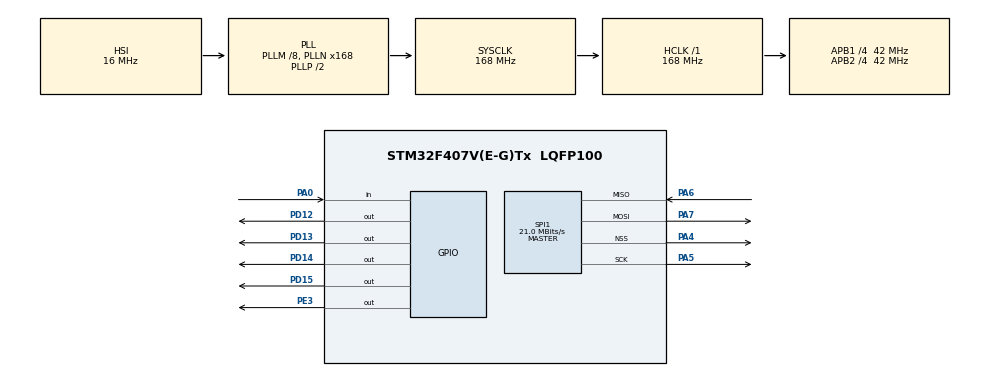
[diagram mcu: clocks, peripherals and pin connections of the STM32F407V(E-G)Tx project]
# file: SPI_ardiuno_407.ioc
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Dma.Request0=SPI1_RX
Dma.Request1=SPI1_TX
Dma.SPI1_RX.0.Direction=DMA_PERIPH_TO_MEMORY
Dma.SPI1_RX.0.FIFOMode=DMA_FIFOMODE_DISABLE
Dma.SPI1_RX.0.Instance=DMA2_Stream0
Dma.SPI1_RX.0.MemDataAlignment=DMA_MDATAALIGN_BYTE
Dma.SPI1_RX.0.MemInc=DMA_MINC_ENABLE
Dma.SPI1_RX.0.Mode=DMA_NORMAL
Dma.SPI1_RX.0.PeriphDataAlignment=DMA_PDATAALIGN_BYTE
Dma.SPI1_RX.0.PeriphInc=DMA_PINC_DISABLE
Dma.SPI1_RX.0.Priority=DMA_PRIORITY_LOW
Dma.SPI1_TX.1.Direction=DMA_MEMORY_TO_PERIPH
Dma.SPI1_TX.1.FIFOMode=DMA_FIFOMODE_DISABLE
Dma.SPI1_TX.1.Instance=DMA2_Stream3
Dma.SPI1_TX.1.MemDataAlignment=DMA_MDATAALIGN_BYTE
Dma.SPI1_TX.1.MemInc=DMA_MINC_ENABLE
Dma.SPI1_TX.1.Mode=DMA_NORMAL
Dma.SPI1_TX.1.PeriphDataAlignment=DMA_PDATAALIGN_BYTE
Dma.SPI1_TX.1.PeriphInc=DMA_PINC_DISABLE
Dma.SPI1_TX.1.Priority=DMA_PRIORITY_LOW
Mcu.Family=STM32F4
Mcu.Name=STM32F407V(E-G)Tx
Mcu.Package=LQFP100
NVIC.DMA2_Stream0_IRQn=true\:0\:0\:false\:false\:true\:false\:true
NVIC.DMA2_Stream3_IRQn=true\:0\:0\:false\:false\:true\:false\:true
NVIC.PriorityGroup=NVIC_PRIORITYGROUP_4
NVIC.SPI1_IRQn=true\:0\:0\:false\:false\:true\:true\:true
PA0-WKUP.Signal=GPIO_Input
PA4.Mode=NSS_Signal_Hard_Output
PA4.Signal=SPI1_NSS
PA5.Mode=Full_Duplex_Master
PA5.Signal=SPI1_SCK
PA6.Mode=Full_Duplex_Master
PA6.Signal=SPI1_MISO
PA7.Mode=Full_Duplex_Master
PA7.Signal=SPI1_MOSI
PC14-OSC32_IN.Mode=LSE-External-Clock-Source
PC14-OSC32_IN.Signal=RCC_OSC32_IN
PC15-OSC32_OUT.Mode=LSE-External-Clock-Source
PC15-OSC32_OUT.Signal=RCC_OSC32_OUT
PD12.Signal=GPIO_Output
PD13.Signal=GPIO_Output
PD14.Signal=GPIO_Output
PD15.Signal=GPIO_Output
PE3.Signal=GPIO_Output
ProjectManager.HeapSize=0x200
ProjectManager.StackSize=0x400
ProjectManager.TargetToolchain=STM32CubeIDE
RCC.48MHZClocksFreq_Value=84000000
RCC.AHBFreq_Value=168000000
RCC.APB1CLKDivider=RCC_HCLK_DIV4
RCC.APB1Freq_Value=42000000
RCC.APB1TimFreq_Value=84000000
RCC.APB2CLKDivider=RCC_HCLK_DIV4
RCC.APB2Freq_Value=42000000
RCC.APB2TimFreq_Value=84000000
RCC.CortexFreq_Value=168000000
RCC.HCLKFreq_Value=168000000
RCC.HSE_VALUE=25000000
RCC.HSI_VALUE=16000000
RCC.LSE_VALUE=32768
RCC.PLLM=8
RCC.PLLN=168
RCC.SYSCLKFreq_VALUE=168000000
RCC.SYSCLKSource=RCC_SYSCLKSOURCE_PLLCLK
RCC.VCOOutputFreq_Value=336000000
SPI1.BaudRatePrescaler=SPI_BAUDRATEPRESCALER_2
SPI1.CalculateBaudRate=21.0 MBits/s
SPI1.Direction=SPI_DIRECTION_2LINES
SPI1.Mode=SPI_MODE_MASTER
SPI1.VirtualNSS=VM_NSSHARD
SPI1.VirtualType=VM_MASTER
board=custom

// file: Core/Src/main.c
/* USER CODE BEGIN Header */
/**
  ******************************************************************************
  * @file           : main.c
  * @brief          : Main program body
  ******************************************************************************
  * @attention
  *
  * <h2><center>&copy; Copyright (c) 2022 STMicroelectronics.
  * All rights reserved.</center></h2>
  *
  * This software component is licensed by ST under BSD 3-Clause license,
  * the "License"; You may not use this file except in compliance with the
  * License. You may obtain a copy of the License at:
  *                        opensource.org/licenses/BSD-3-Clause
  *
  ******************************************************************************
  */
/* USER CODE END Header */
#include "main.h"

SPI_HandleTypeDef hspi1;
DMA_HandleTypeDef hdma_spi1_rx;
DMA_HandleTypeDef hdma_spi1_tx;

/* USER CODE BEGIN PV */
uint8_t Tx_buff[20],i=0;
/* USER CODE END PV */

void SystemClock_Config(void);
static void MX_GPIO_Init(void);
static void MX_DMA_Init(void);
static void MX_SPI1_Init(void);

int main(void)
{

  /* MCU Configuration--------------------------------------------------------*/

  /* Reset of all peripherals, Initializes the Flash interface and the Systick. */
  HAL_Init();

  /* Configure the system clock */
  SystemClock_Config();

  /* Initialize all configured peripherals */
  MX_GPIO_Init();
  MX_DMA_Init();
  MX_SPI1_Init();

  /* Infinite loop */
  /* USER CODE BEGIN WHILE */
  while (1)
  {
	  HAL_GPIO_WritePin(GPIOE, GPIO_PIN_3, GPIO_PIN_RESET);
	  sprintf(Tx_buff,"tx data buff: %d\r\n",i);
	  HAL_SPI_Transmit(&hspi1, Tx_buff, strlen(Tx_buff), 1000);
	  HAL_GPIO_WritePin(GPIOE, GPIO_PIN_3, GPIO_PIN_SET);

	  HAL_GPIO_TogglePin(GPIOD, GPIO_PIN_13);
	  HAL_Delay(2000);
	  i++;
    /* USER CODE END WHILE */

  }
}

void SystemClock_Config(void)
{
  RCC_OscInitTypeDef RCC_OscInitStruct = {0};
  RCC_ClkInitTypeDef RCC_ClkInitStruct = {0};

  /** Configure the main internal regulator output voltage
  */
  __HAL_RCC_PWR_CLK_ENABLE();
  __HAL_PWR_VOLTAGESCALING_CONFIG(PWR_REGULATOR_VOLTAGE_SCALE1);
  /** Initializes the RCC Oscillators according to the specified parameters
  * in the RCC_OscInitTypeDef structure.
  */
  RCC_OscInitStruct.OscillatorType = RCC_OSCILLATORTYPE_HSI;
  RCC_OscInitStruct.HSIState = RCC_HSI_ON;
  RCC_OscInitStruct.HSICalibrationValue = RCC_HSICALIBRATION_DEFAULT;
  RCC_OscInitStruct.PLL.PLLState = RCC_PLL_ON;
  RCC_OscInitStruct.PLL.PLLSource = RCC_PLLSOURCE_HSI;
  RCC_OscInitStruct.PLL.PLLM = 8;
  RCC_OscInitStruct.PLL.PLLN = 168;
  RCC_OscInitStruct.PLL.PLLP = RCC_PLLP_DIV2;
  RCC_OscInitStruct.PLL.PLLQ = 4;
  if (HAL_RCC_OscConfig(&RCC_OscInitStruct) != HAL_OK)
  {
    Error_Handler();
  }
  /** Initializes the CPU, AHB and APB buses clocks
  */
  RCC_ClkInitStruct.ClockType = RCC_CLOCKTYPE_HCLK|RCC_CLOCKTYPE_SYSCLK
                              |RCC_CLOCKTYPE_PCLK1|RCC_CLOCKTYPE_PCLK2;
  RCC_ClkInitStruct.SYSCLKSource = RCC_SYSCLKSOURCE_PLLCLK;
  RCC_ClkInitStruct.AHBCLKDivider = RCC_SYSCLK_DIV1;
  RCC_ClkInitStruct.APB1CLKDivider = RCC_HCLK_DIV4;
  RCC_ClkInitStruct.APB2CLKDivider = RCC_HCLK_DIV4;

  if (HAL_RCC_ClockConfig(&RCC_ClkInitStruct, FLASH_LATENCY_5) != HAL_OK)
  {
    Error_Handler();
  }
}

static void MX_SPI1_Init(void)
{

  /* SPI1 parameter configuration*/
  hspi1.Instance = SPI1;
  hspi1.Init.Mode = SPI_MODE_MASTER;
  hspi1.Init.Direction = SPI_DIRECTION_2LINES;
  hspi1.Init.DataSize = SPI_DATASIZE_8BIT;
  hspi1.Init.CLKPolarity = SPI_POLARITY_LOW;
  hspi1.Init.CLKPhase = SPI_PHASE_1EDGE;
  hspi1.Init.NSS = SPI_NSS_HARD_OUTPUT;
  hspi1.Init.BaudRatePrescaler = SPI_BAUDRATEPRESCALER_2;
  hspi1.Init.FirstBit = SPI_FIRSTBIT_MSB;
  hspi1.Init.TIMode = SPI_TIMODE_DISABLE;
  hspi1.Init.CRCCalculation = SPI_CRCCALCULATION_DISABLE;
  hspi1.Init.CRCPolynomial = 10;
  if (HAL_SPI_Init(&hspi1) != HAL_OK)
  {
    Error_Handler();
  }

}

static void MX_DMA_Init(void)
{

  /* DMA controller clock enable */
  __HAL_RCC_DMA2_CLK_ENABLE();

  /* DMA interrupt init */
  /* DMA2_Stream0_IRQn interrupt configuration */
  HAL_NVIC_SetPriority(DMA2_Stream0_IRQn, 0, 0);
  HAL_NVIC_EnableIRQ(DMA2_Stream0_IRQn);
  /* DMA2_Stream3_IRQn interrupt configuration */
  HAL_NVIC_SetPriority(DMA2_Stream3_IRQn, 0, 0);
  HAL_NVIC_EnableIRQ(DMA2_Stream3_IRQn);

}

static void MX_GPIO_Init(void)
{
  GPIO_InitTypeDef GPIO_InitStruct = {0};

  /* GPIO Ports Clock Enable */
  __HAL_RCC_GPIOE_CLK_ENABLE();
  __HAL_RCC_GPIOC_CLK_ENABLE();
  __HAL_RCC_GPIOA_CLK_ENABLE();
  __HAL_RCC_GPIOD_CLK_ENABLE();

  /*Configure GPIO pin Output Level */
  HAL_GPIO_WritePin(GPIOE, GPIO_PIN_3, GPIO_PIN_RESET);

  /*Configure GPIO pin Output Level */
  HAL_GPIO_WritePin(GPIOD, GPIO_PIN_12|GPIO_PIN_13|GPIO_PIN_14|GPIO_PIN_15, GPIO_PIN_RESET);

  /*Configure GPIO pin : PE3 */
  GPIO_InitStruct.Pin = GPIO_PIN_3;
  GPIO_InitStruct.Mode = GPIO_MODE_OUTPUT_PP;
  GPIO_InitStruct.Pull = GPIO_NOPULL;
  GPIO_InitStruct.Speed = GPIO_SPEED_FREQ_LOW;
  HAL_GPIO_Init(GPIOE, &GPIO_InitStruct);

  /*Configure GPIO pin : PA0 */
  GPIO_InitStruct.Pin = GPIO_PIN_0;
  GPIO_InitStruct.Mode = GPIO_MODE_INPUT;
  GPIO_InitStruct.Pull = GPIO_NOPULL;
  HAL_GPIO_Init(GPIOA, &GPIO_InitStruct);

  /*Configure GPIO pins : PD12 PD13 PD14 PD15 */
  GPIO_InitStruct.Pin = GPIO_PIN_12|GPIO_PIN_13|GPIO_PIN_14|GPIO_PIN_15;
  GPIO_InitStruct.Mode = GPIO_MODE_OUTPUT_PP;
  GPIO_InitStruct.Pull = GPIO_NOPULL;
  GPIO_InitStruct.Speed = GPIO_SPEED_FREQ_LOW;
  HAL_GPIO_Init(GPIOD, &GPIO_InitStruct);

}

void Error_Handler(void)
{
  __disable_irq();
  while (1)
  {
  }
}

/************************ (C) COPYRIGHT STMicroelectronics *****END OF FILE****/
